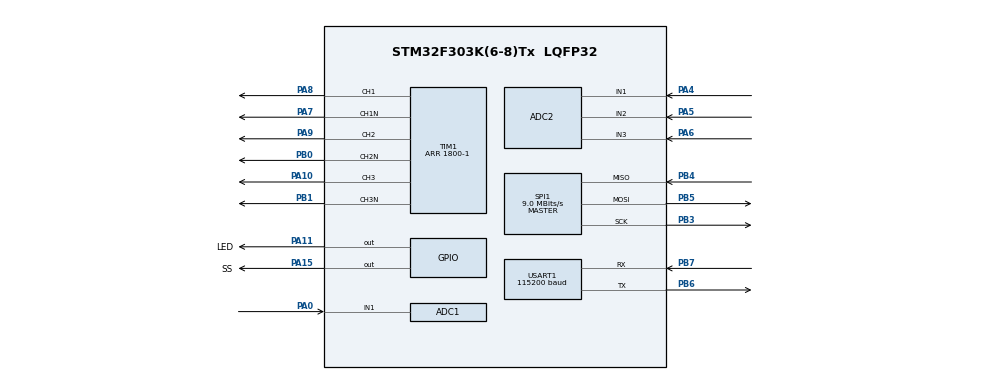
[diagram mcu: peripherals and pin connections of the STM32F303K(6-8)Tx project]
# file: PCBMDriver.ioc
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ADC1.Channel-1\#ChannelRegularConversion=ADC_CHANNEL_1
ADC1.NbrOfConversionFlag=1
ADC1.Offset-1\#ChannelRegularConversion=0
ADC1.OffsetNumber-1\#ChannelRegularConversion=ADC_OFFSET_NONE
ADC1.Rank-1\#ChannelRegularConversion=1
ADC1.SamplingTime-1\#ChannelRegularConversion=ADC_SAMPLETIME_1CYCLE_5
ADC1.SamplingTimeOPAMP-1\#ChannelRegularConversion=ADC_SAMPLETIME_61CYCLES_5
ADC1.SubFamily=STM32F303x8
ADC1.master=1
ADC2.EOCSelection=ADC_EOC_SEQ_CONV
ADC2.EnableRegularConversion=DISABLE
ADC2.ExternalTrigInjecConv=ADC_EXTERNALTRIGINJECCONV_T1_TRGO
ADC2.InjNumberOfConversion=3
ADC2.InjectedChannel-1\#ChannelInjectedConversion=ADC_CHANNEL_1
ADC2.InjectedChannel-2\#ChannelInjectedConversion=ADC_CHANNEL_2
ADC2.InjectedChannel-3\#ChannelInjectedConversion=ADC_CHANNEL_3
ADC2.InjectedOffset-1\#ChannelInjectedConversion=0
ADC2.InjectedOffset-2\#ChannelInjectedConversion=0
ADC2.InjectedOffset-3\#ChannelInjectedConversion=0
ADC2.InjectedOffsetNumber-1\#ChannelInjectedConversion=ADC_OFFSET_NONE
ADC2.InjectedOffsetNumber-2\#ChannelInjectedConversion=ADC_OFFSET_NONE
ADC2.InjectedOffsetNumber-3\#ChannelInjectedConversion=ADC_OFFSET_NONE
ADC2.InjectedRank-1\#ChannelInjectedConversion=1
ADC2.InjectedRank-2\#ChannelInjectedConversion=2
ADC2.InjectedRank-3\#ChannelInjectedConversion=3
ADC2.InjectedSamplingTime-1\#ChannelInjectedConversion=ADC_SAMPLETIME_1CYCLE_5
ADC2.InjectedSamplingTime-2\#ChannelInjectedConversion=ADC_SAMPLETIME_1CYCLE_5
ADC2.InjectedSamplingTime-3\#ChannelInjectedConversion=ADC_SAMPLETIME_1CYCLE_5
ADC2.InjectedSamplingTimeOPAMP-1\#ChannelInjectedConversion=ADC_SAMPLETIME_61CYCLES_5
ADC2.InjectedSamplingTimeOPAMP-2\#ChannelInjectedConversion=ADC_SAMPLETIME_61CYCLES_5
ADC2.InjectedSamplingTimeOPAMP-3\#ChannelInjectedConversion=ADC_SAMPLETIME_61CYCLES_5
ADC2.Rank1_Channel=ADC_CHANNEL_1
ADC2.Rank2_Channel=ADC_CHANNEL_2
ADC2.Rank3_Channel=ADC_CHANNEL_3
ADC2.SubFamily=STM32F303x8
Dma.Request0=SPI1_RX
Dma.Request1=SPI1_TX
Dma.SPI1_RX.0.Direction=DMA_PERIPH_TO_MEMORY
Dma.SPI1_RX.0.Instance=DMA1_Channel2
Dma.SPI1_RX.0.MemDataAlignment=DMA_MDATAALIGN_BYTE
Dma.SPI1_RX.0.MemInc=DMA_MINC_ENABLE
Dma.SPI1_RX.0.Mode=DMA_NORMAL
Dma.SPI1_RX.0.PeriphDataAlignment=DMA_PDATAALIGN_BYTE
Dma.SPI1_RX.0.PeriphInc=DMA_PINC_DISABLE
Dma.SPI1_RX.0.Priority=DMA_PRIORITY_LOW
Dma.SPI1_TX.1.Direction=DMA_MEMORY_TO_PERIPH
Dma.SPI1_TX.1.Instance=DMA1_Channel3
Dma.SPI1_TX.1.MemDataAlignment=DMA_MDATAALIGN_BYTE
Dma.SPI1_TX.1.MemInc=DMA_MINC_ENABLE
Dma.SPI1_TX.1.Mode=DMA_NORMAL
Dma.SPI1_TX.1.PeriphDataAlignment=DMA_PDATAALIGN_BYTE
Dma.SPI1_TX.1.PeriphInc=DMA_PINC_DISABLE
Dma.SPI1_TX.1.Priority=DMA_PRIORITY_LOW
Mcu.Family=STM32F3
Mcu.Name=STM32F303K(6-8)Tx
Mcu.Package=LQFP32
NVIC.ADC1_2_IRQn=true\:0\:0\:false\:false\:true\:true\:true\:true
NVIC.DMA1_Channel2_IRQn=true\:0\:0\:false\:false\:true\:false\:true\:true
NVIC.DMA1_Channel3_IRQn=true\:0\:0\:false\:false\:true\:false\:true\:true
NVIC.PriorityGroup=NVIC_PRIORITYGROUP_4
NVIC.SPI1_IRQn=true\:0\:0\:false\:false\:true\:true\:true\:true
NVIC.TIM2_IRQn=true\:0\:0\:false\:false\:true\:true\:true\:true
NVIC.USART1_IRQn=true\:0\:0\:false\:false\:true\:true\:true\:true
PA0.Mode=IN1-Single-Ended
PA0.Signal=ADC1_IN1
PA10.Signal=S_TIM1_CH3
PA11.GPIO_Label=LED
PA11.Signal=GPIO_Output
PA13.Signal=SYS_JTMS-SWDIO
PA14.Signal=SYS_JTCK-SWCLK
PA15.GPIO_Label=SS
PA15.Signal=GPIO_Output
PA4.Mode=IN1-Single-Ended
PA4.Signal=ADC2_IN1
PA5.Mode=IN2-Single-Ended
PA5.Signal=ADC2_IN2
PA6.Mode=IN3-Single-Ended
PA6.Signal=ADC2_IN3
PA7.Mode=PWM Generation1 CH1 CH1N
PA7.Signal=TIM1_CH1N
PA8.Signal=S_TIM1_CH1
PA9.Signal=S_TIM1_CH2
PB0.Mode=PWM Generation2 CH2 CH2N
PB0.Signal=TIM1_CH2N
PB1.Mode=PWM Generation3 CH3 CH3N
PB1.Signal=TIM1_CH3N
PB3.Mode=Full_Duplex_Master
PB3.Signal=SPI1_SCK
PB4.Mode=Full_Duplex_Master
PB4.Signal=SPI1_MISO
PB5.Mode=Full_Duplex_Master
PB5.Signal=SPI1_MOSI
PB6.Mode=Asynchronous
PB6.Signal=USART1_TX
PB7.Mode=Asynchronous
PB7.Signal=USART1_RX
PF0\ /\ OSC_IN.Mode=HSE-External-Oscillator
PF0\ /\ OSC_IN.Signal=RCC_OSC_IN
PF1\ /\ OSC_OUT.Mode=HSE-External-Oscillator
PF1\ /\ OSC_OUT.Signal=RCC_OSC_OUT
ProjectManager.HeapSize=0x200
ProjectManager.StackSize=0x400
ProjectManager.TargetToolchain=STM32CubeIDE
RCC.AHBFreq_Value=72000000
RCC.APB1CLKDivider=RCC_HCLK_DIV2
RCC.APB1Freq_Value=36000000
RCC.APB1TimFreq_Value=72000000
RCC.APB2Freq_Value=72000000
RCC.APB2TimFreq_Value=72000000
RCC.CortexFreq_Value=72000000
RCC.HCLKFreq_Value=72000000
RCC.HSE_VALUE=16000000
RCC.HSI_VALUE=8000000
RCC.PLLMUL=RCC_PLL_MUL9
RCC.PLLSourceVirtual=RCC_PLLSOURCE_HSE
RCC.RCC_PLLsource_Clock_Source_FROM_HSE=RCC_HSE_PREDIV_DIV2
RCC.SYSCLKFreq_VALUE=72000000
RCC.SYSCLKSourceVirtual=RCC_SYSCLKSOURCE_PLLCLK
SH.S_TIM1_CH1.0=TIM1_CH1,PWM Generation1 CH1 CH1N
SH.S_TIM1_CH2.0=TIM1_CH2,PWM Generation2 CH2 CH2N
SH.S_TIM1_CH3.0=TIM1_CH3,PWM Generation3 CH3 CH3N
SPI1.BaudRatePrescaler=SPI_BAUDRATEPRESCALER_8
SPI1.CLKPhase=SPI_PHASE_2EDGE
SPI1.CalculateBaudRate=9.0 MBits/s
SPI1.DataSize=SPI_DATASIZE_8BIT
SPI1.Direction=SPI_DIRECTION_2LINES
SPI1.Mode=SPI_MODE_MASTER
SPI1.VirtualType=VM_MASTER
TIM1.Channel-PWM\ Generation1\ CH1\ CH1N=TIM_CHANNEL_1
TIM1.Channel-PWM\ Generation2\ CH2\ CH2N=TIM_CHANNEL_2
TIM1.Channel-PWM\ Generation3\ CH3\ CH3N=TIM_CHANNEL_3
TIM1.CounterMode=TIM_COUNTERMODE_CENTERALIGNED1
TIM1.DeadTime=100
TIM1.Period=1800-1
TIM1.RepetitionCounter=1
TIM1.TIM_MasterOutputTrigger=TIM_TRGO_UPDATE
TIM2.Period=1000-1
TIM2.Prescaler=72-1
USART1.BaudRate=115200
USART1.VirtualMode-Asynchronous=VM_ASYNC
VP_TIM2_VS_ClockSourceINT.Mode=Internal
board=custom

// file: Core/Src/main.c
/* USER CODE BEGIN Header */
/**
  ******************************************************************************
  * @file           : main.c
  * @brief          : Main program body
  ******************************************************************************
  * @attention
  *
  * Copyright (c) 2024 STMicroelectronics.
  * All rights reserved.
  *
  * This software is licensed under terms that can be found in the LICENSE file
  * in the root directory of this software component.
  * If no LICENSE file comes with this software, it is provided AS-IS.
  *
  ******************************************************************************
  */
/* USER CODE END Header */
#include "main.h"

ADC_HandleTypeDef hadc1;
ADC_HandleTypeDef hadc2;

SPI_HandleTypeDef hspi1;
DMA_HandleTypeDef hdma_spi1_rx;
DMA_HandleTypeDef hdma_spi1_tx;

TIM_HandleTypeDef htim1;
TIM_HandleTypeDef htim2;

UART_HandleTypeDef huart1;

void SystemClock_Config(void);
static void MX_GPIO_Init(void);
static void MX_DMA_Init(void);
static void MX_ADC1_Init(void);
static void MX_ADC2_Init(void);
static void MX_SPI1_Init(void);
static void MX_TIM1_Init(void);
static void MX_TIM2_Init(void);
static void MX_USART1_UART_Init(void);

int main(void)
{

  /* MCU Configuration--------------------------------------------------------*/

  /* Reset of all peripherals, Initializes the Flash interface and the Systick. */
  HAL_Init();

  /* Configure the system clock */
  SystemClock_Config();

  /* Initialize all configured peripherals */
  MX_GPIO_Init();
  MX_DMA_Init();
  MX_ADC1_Init();
  MX_ADC2_Init();
  MX_SPI1_Init();
  MX_TIM1_Init();
  MX_TIM2_Init();
  MX_USART1_UART_Init();
  /* USER CODE BEGIN 2 */

  main_();
  /* USER CODE END 2 */

  /* Infinite loop */
  while (1)
  {

  }
}

void SystemClock_Config(void)
{
  LL_FLASH_SetLatency(LL_FLASH_LATENCY_2);
  while(LL_FLASH_GetLatency()!= LL_FLASH_LATENCY_2)
  {
  }
  LL_RCC_HSE_Enable();

   /* Wait till HSE is ready */
  while(LL_RCC_HSE_IsReady() != 1)
  {

  }
  LL_RCC_PLL_ConfigDomain_SYS(LL_RCC_PLLSOURCE_HSE_DIV_2, LL_RCC_PLL_MUL_9);
  LL_RCC_PLL_Enable();

   /* Wait till PLL is ready */
  while(LL_RCC_PLL_IsReady() != 1)
  {

  }
  LL_RCC_SetAHBPrescaler(LL_RCC_SYSCLK_DIV_1);
  LL_RCC_SetAPB1Prescaler(LL_RCC_APB1_DIV_2);
  LL_RCC_SetAPB2Prescaler(LL_RCC_APB2_DIV_1);
  LL_RCC_SetSysClkSource(LL_RCC_SYS_CLKSOURCE_PLL);

   /* Wait till System clock is ready */
  while(LL_RCC_GetSysClkSource() != LL_RCC_SYS_CLKSOURCE_STATUS_PLL)
  {

  }
  LL_SetSystemCoreClock(72000000);

   /* Update the time base */
  if (HAL_InitTick (TICK_INT_PRIORITY) != HAL_OK)
  {
    Error_Handler();
  }
  LL_RCC_SetUSARTClockSource(LL_RCC_USART1_CLKSOURCE_PCLK1);
  LL_RCC_SetTIMClockSource(LL_RCC_TIM1_CLKSOURCE_PCLK2);
  LL_RCC_SetADCClockSource(LL_RCC_ADC12_CLKSRC_PLL_DIV_1);
}

static void MX_ADC1_Init(void)
{

  ADC_MultiModeTypeDef multimode = {0};
  ADC_ChannelConfTypeDef sConfig = {0};

  /** Common config
  */
  hadc1.Instance = ADC1;
  hadc1.Init.ClockPrescaler = ADC_CLOCK_ASYNC_DIV1;
  hadc1.Init.Resolution = ADC_RESOLUTION_12B;
  hadc1.Init.ScanConvMode = ADC_SCAN_DISABLE;
  hadc1.Init.ContinuousConvMode = DISABLE;
  hadc1.Init.DiscontinuousConvMode = DISABLE;
  hadc1.Init.ExternalTrigConvEdge = ADC_EXTERNALTRIGCONVEDGE_NONE;
  hadc1.Init.ExternalTrigConv = ADC_SOFTWARE_START;
  hadc1.Init.DataAlign = ADC_DATAALIGN_RIGHT;
  hadc1.Init.NbrOfConversion = 1;
  hadc1.Init.DMAContinuousRequests = DISABLE;
  hadc1.Init.EOCSelection = ADC_EOC_SINGLE_CONV;
  hadc1.Init.LowPowerAutoWait = DISABLE;
  hadc1.Init.Overrun = ADC_OVR_DATA_OVERWRITTEN;
  if (HAL_ADC_Init(&hadc1) != HAL_OK)
  {
    Error_Handler();
  }

  /** Configure the ADC multi-mode
  */
  multimode.Mode = ADC_MODE_INDEPENDENT;
  if (HAL_ADCEx_MultiModeConfigChannel(&hadc1, &multimode) != HAL_OK)
  {
    Error_Handler();
  }

  /** Configure Regular Channel
  */
  sConfig.Channel = ADC_CHANNEL_1;
  sConfig.Rank = ADC_REGULAR_RANK_1;
  sConfig.SingleDiff = ADC_SINGLE_ENDED;
  sConfig.SamplingTime = ADC_SAMPLETIME_1CYCLE_5;
  sConfig.OffsetNumber = ADC_OFFSET_NONE;
  sConfig.Offset = 0;
  if (HAL_ADC_ConfigChannel(&hadc1, &sConfig) != HAL_OK)
  {
    Error_Handler();
  }

}

static void MX_ADC2_Init(void)
{

  ADC_InjectionConfTypeDef sConfigInjected = {0};

  /** Common config
  */
  hadc2.Instance = ADC2;
  hadc2.Init.ClockPrescaler = ADC_CLOCK_ASYNC_DIV1;
  hadc2.Init.Resolution = ADC_RESOLUTION_12B;
  hadc2.Init.ScanConvMode = ADC_SCAN_ENABLE;
  hadc2.Init.ContinuousConvMode = DISABLE;
  hadc2.Init.DiscontinuousConvMode = DISABLE;
  hadc2.Init.DataAlign = ADC_DATAALIGN_RIGHT;
  hadc2.Init.NbrOfConversion = 1;
  hadc2.Init.DMAContinuousRequests = DISABLE;
  hadc2.Init.EOCSelection = ADC_EOC_SEQ_CONV;
  hadc2.Init.LowPowerAutoWait = DISABLE;
  hadc2.Init.Overrun = ADC_OVR_DATA_OVERWRITTEN;
  if (HAL_ADC_Init(&hadc2) != HAL_OK)
  {
    Error_Handler();
  }

  /** Configure Injected Channel
  */
  sConfigInjected.InjectedChannel = ADC_CHANNEL_1;
  sConfigInjected.InjectedRank = ADC_INJECTED_RANK_1;
  sConfigInjected.InjectedSingleDiff = ADC_SINGLE_ENDED;
  sConfigInjected.InjectedNbrOfConversion = 3;
  sConfigInjected.InjectedSamplingTime = ADC_SAMPLETIME_1CYCLE_5;
  sConfigInjected.ExternalTrigInjecConvEdge = ADC_EXTERNALTRIGINJECCONV_EDGE_RISING;
  sConfigInjected.ExternalTrigInjecConv = ADC_EXTERNALTRIGINJECCONV_T1_TRGO;
  sConfigInjected.AutoInjectedConv = DISABLE;
  sConfigInjected.InjectedDiscontinuousConvMode = DISABLE;
  sConfigInjected.QueueInjectedContext = DISABLE;
  sConfigInjected.InjectedOffset = 0;
  sConfigInjected.InjectedOffsetNumber = ADC_OFFSET_NONE;
  if (HAL_ADCEx_InjectedConfigChannel(&hadc2, &sConfigInjected) != HAL_OK)
  {
    Error_Handler();
  }

  /** Configure Injected Channel
  */
  sConfigInjected.InjectedChannel = ADC_CHANNEL_2;
  sConfigInjected.InjectedRank = ADC_INJECTED_RANK_2;
  if (HAL_ADCEx_InjectedConfigChannel(&hadc2, &sConfigInjected) != HAL_OK)
  {
    Error_Handler();
  }

  /** Configure Injected Channel
  */
  sConfigInjected.InjectedChannel = ADC_CHANNEL_3;
  sConfigInjected.InjectedRank = ADC_INJECTED_RANK_3;
  if (HAL_ADCEx_InjectedConfigChannel(&hadc2, &sConfigInjected) != HAL_OK)
  {
    Error_Handler();
  }

}

static void MX_SPI1_Init(void)
{

  /* SPI1 parameter configuration*/
  hspi1.Instance = SPI1;
  hspi1.Init.Mode = SPI_MODE_MASTER;
  hspi1.Init.Direction = SPI_DIRECTION_2LINES;
  hspi1.Init.DataSize = SPI_DATASIZE_8BIT;
  hspi1.Init.CLKPolarity = SPI_POLARITY_LOW;
  hspi1.Init.CLKPhase = SPI_PHASE_2EDGE;
  hspi1.Init.NSS = SPI_NSS_SOFT;
  hspi1.Init.BaudRatePrescaler = SPI_BAUDRATEPRESCALER_8;
  hspi1.Init.FirstBit = SPI_FIRSTBIT_MSB;
  hspi1.Init.TIMode = SPI_TIMODE_DISABLE;
  hspi1.Init.CRCCalculation = SPI_CRCCALCULATION_DISABLE;
  hspi1.Init.CRCPolynomial = 7;
  hspi1.Init.CRCLength = SPI_CRC_LENGTH_DATASIZE;
  hspi1.Init.NSSPMode = SPI_NSS_PULSE_DISABLE;
  if (HAL_SPI_Init(&hspi1) != HAL_OK)
  {
    Error_Handler();
  }

}

static void MX_TIM1_Init(void)
{

  TIM_MasterConfigTypeDef sMasterConfig = {0};
  TIM_OC_InitTypeDef sConfigOC = {0};
  TIM_BreakDeadTimeConfigTypeDef sBreakDeadTimeConfig = {0};

  htim1.Instance = TIM1;
  htim1.Init.Prescaler = 0;
  htim1.Init.CounterMode = TIM_COUNTERMODE_CENTERALIGNED1;
  htim1.Init.Period = 1800-1;
  htim1.Init.ClockDivision = TIM_CLOCKDIVISION_DIV1;
  htim1.Init.RepetitionCounter = 1;
  htim1.Init.AutoReloadPreload = TIM_AUTORELOAD_PRELOAD_DISABLE;
  if (HAL_TIM_PWM_Init(&htim1) != HAL_OK)
  {
    Error_Handler();
  }
  sMasterConfig.MasterOutputTrigger = TIM_TRGO_UPDATE;
  sMasterConfig.MasterOutputTrigger2 = TIM_TRGO2_RESET;
  sMasterConfig.MasterSlaveMode = TIM_MASTERSLAVEMODE_DISABLE;
  if (HAL_TIMEx_MasterConfigSynchronization(&htim1, &sMasterConfig) != HAL_OK)
  {
    Error_Handler();
  }
  sConfigOC.OCMode = TIM_OCMODE_PWM1;
  sConfigOC.Pulse = 0;
  sConfigOC.OCPolarity = TIM_OCPOLARITY_HIGH;
  sConfigOC.OCNPolarity = TIM_OCNPOLARITY_HIGH;
  sConfigOC.OCFastMode = TIM_OCFAST_DISABLE;
  sConfigOC.OCIdleState = TIM_OCIDLESTATE_RESET;
  sConfigOC.OCNIdleState = TIM_OCNIDLESTATE_RESET;
  if (HAL_TIM_PWM_ConfigChannel(&htim1, &sConfigOC, TIM_CHANNEL_1) != HAL_OK)
  {
    Error_Handler();
  }
  if (HAL_TIM_PWM_ConfigChannel(&htim1, &sConfigOC, TIM_CHANNEL_2) != HAL_OK)
  {
    Error_Handler();
  }
  if (HAL_TIM_PWM_ConfigChannel(&htim1, &sConfigOC, TIM_CHANNEL_3) != HAL_OK)
  {
    Error_Handler();
  }
  sBreakDeadTimeConfig.OffStateRunMode = TIM_OSSR_DISABLE;
  sBreakDeadTimeConfig.OffStateIDLEMode = TIM_OSSI_DISABLE;
  sBreakDeadTimeConfig.LockLevel = TIM_LOCKLEVEL_OFF;
  sBreakDeadTimeConfig.DeadTime = 100;
  sBreakDeadTimeConfig.BreakState = TIM_BREAK_DISABLE;
  sBreakDeadTimeConfig.BreakPolarity = TIM_BREAKPOLARITY_HIGH;
  sBreakDeadTimeConfig.BreakFilter = 0;
  sBreakDeadTimeConfig.Break2State = TIM_BREAK2_DISABLE;
  sBreakDeadTimeConfig.Break2Polarity = TIM_BREAK2POLARITY_HIGH;
  sBreakDeadTimeConfig.Break2Filter = 0;
  sBreakDeadTimeConfig.AutomaticOutput = TIM_AUTOMATICOUTPUT_DISABLE;
  if (HAL_TIMEx_ConfigBreakDeadTime(&htim1, &sBreakDeadTimeConfig) != HAL_OK)
  {
    Error_Handler();
  }
  HAL_TIM_MspPostInit(&htim1);

}

static void MX_TIM2_Init(void)
{

  TIM_ClockConfigTypeDef sClockSourceConfig = {0};
  TIM_MasterConfigTypeDef sMasterConfig = {0};

  htim2.Instance = TIM2;
  htim2.Init.Prescaler = 72-1;
  htim2.Init.CounterMode = TIM_COUNTERMODE_UP;
  htim2.Init.Period = 1000-1;
  htim2.Init.ClockDivision = TIM_CLOCKDIVISION_DIV1;
  htim2.Init.AutoReloadPreload = TIM_AUTORELOAD_PRELOAD_DISABLE;
  if (HAL_TIM_Base_Init(&htim2) != HAL_OK)
  {
    Error_Handler();
  }
  sClockSourceConfig.ClockSource = TIM_CLOCKSOURCE_INTERNAL;
  if (HAL_TIM_ConfigClockSource(&htim2, &sClockSourceConfig) != HAL_OK)
  {
    Error_Handler();
  }
  sMasterConfig.MasterOutputTrigger = TIM_TRGO_RESET;
  sMasterConfig.MasterSlaveMode = TIM_MASTERSLAVEMODE_DISABLE;
  if (HAL_TIMEx_MasterConfigSynchronization(&htim2, &sMasterConfig) != HAL_OK)
  {
    Error_Handler();
  }

}

static void MX_USART1_UART_Init(void)
{

  huart1.Instance = USART1;
  huart1.Init.BaudRate = 115200;
  huart1.Init.WordLength = UART_WORDLENGTH_8B;
  huart1.Init.StopBits = UART_STOPBITS_1;
  huart1.Init.Parity = UART_PARITY_NONE;
  huart1.Init.Mode = UART_MODE_TX_RX;
  huart1.Init.HwFlowCtl = UART_HWCONTROL_NONE;
  huart1.Init.OverSampling = UART_OVERSAMPLING_16;
  huart1.Init.OneBitSampling = UART_ONE_BIT_SAMPLE_DISABLE;
  huart1.AdvancedInit.AdvFeatureInit = UART_ADVFEATURE_NO_INIT;
  if (HAL_UART_Init(&huart1) != HAL_OK)
  {
    Error_Handler();
  }

}

static void MX_DMA_Init(void)
{

  /* DMA controller clock enable */
  __HAL_RCC_DMA1_CLK_ENABLE();

  /* DMA interrupt init */
  /* DMA1_Channel2_IRQn interrupt configuration */
  HAL_NVIC_SetPriority(DMA1_Channel2_IRQn, 0, 0);
  HAL_NVIC_EnableIRQ(DMA1_Channel2_IRQn);
  /* DMA1_Channel3_IRQn interrupt configuration */
  HAL_NVIC_SetPriority(DMA1_Channel3_IRQn, 0, 0);
  HAL_NVIC_EnableIRQ(DMA1_Channel3_IRQn);

}

static void MX_GPIO_Init(void)
{
  LL_GPIO_InitTypeDef GPIO_InitStruct = {0};

  /* GPIO Ports Clock Enable */
  LL_AHB1_GRP1_EnableClock(LL_AHB1_GRP1_PERIPH_GPIOF);
  LL_AHB1_GRP1_EnableClock(LL_AHB1_GRP1_PERIPH_GPIOA);
  LL_AHB1_GRP1_EnableClock(LL_AHB1_GRP1_PERIPH_GPIOB);

  /**/
  LL_GPIO_ResetOutputPin(GPIOA, LED_Pin|SS_Pin);

  /**/
  GPIO_InitStruct.Pin = LED_Pin|SS_Pin;
  GPIO_InitStruct.Mode = LL_GPIO_MODE_OUTPUT;
  GPIO_InitStruct.Speed = LL_GPIO_SPEED_FREQ_LOW;
  GPIO_InitStruct.OutputType = LL_GPIO_OUTPUT_PUSHPULL;
  GPIO_InitStruct.Pull = LL_GPIO_PULL_NO;
  LL_GPIO_Init(GPIOA, &GPIO_InitStruct);

}

void Error_Handler(void)
{
  __disable_irq();
  while (1)
  {
  }
}
